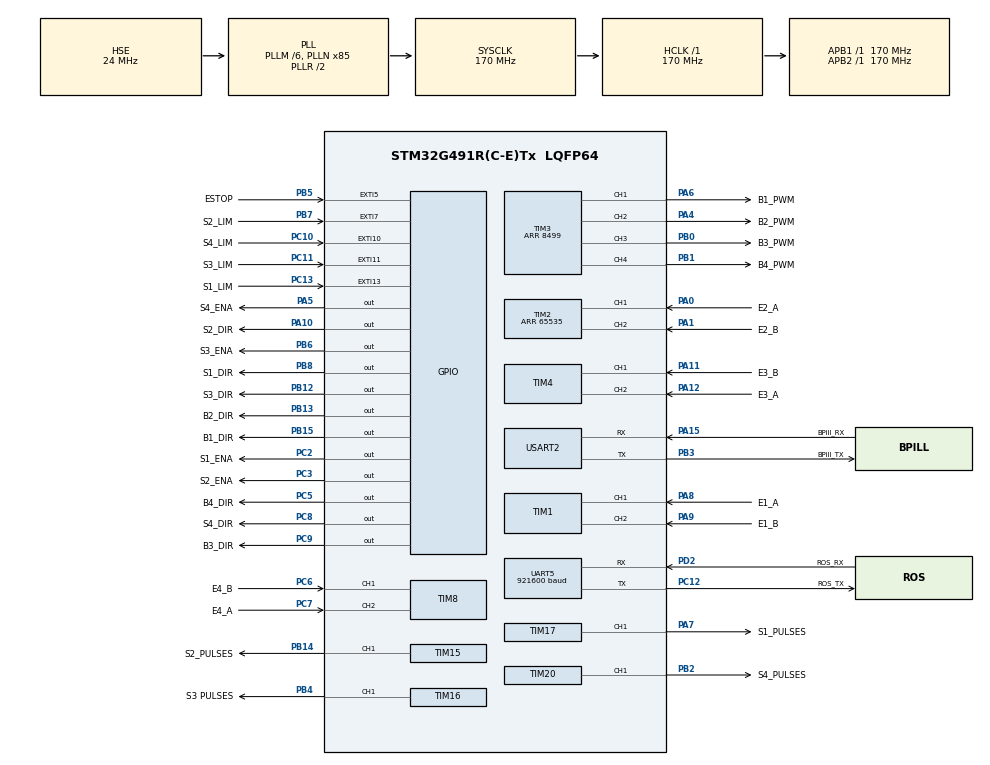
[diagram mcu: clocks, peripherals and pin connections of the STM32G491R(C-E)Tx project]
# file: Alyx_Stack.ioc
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Dma.Request0=UART5_RX
Dma.Request1=UART5_TX
Dma.UART5_RX.0.Direction=DMA_PERIPH_TO_MEMORY
Dma.UART5_RX.0.EventEnable=DISABLE
Dma.UART5_RX.0.Instance=DMA1_Channel1
Dma.UART5_RX.0.MemDataAlignment=DMA_MDATAALIGN_BYTE
Dma.UART5_RX.0.MemInc=DMA_MINC_ENABLE
Dma.UART5_RX.0.Mode=DMA_CIRCULAR
Dma.UART5_RX.0.PeriphDataAlignment=DMA_PDATAALIGN_BYTE
Dma.UART5_RX.0.PeriphInc=DMA_PINC_DISABLE
Dma.UART5_RX.0.Polarity=HAL_DMAMUX_REQ_GEN_RISING
Dma.UART5_RX.0.Priority=DMA_PRIORITY_HIGH
Dma.UART5_RX.0.RequestNumber=1
Dma.UART5_RX.0.SignalID=NONE
Dma.UART5_RX.0.SyncEnable=DISABLE
Dma.UART5_RX.0.SyncPolarity=HAL_DMAMUX_SYNC_NO_EVENT
Dma.UART5_RX.0.SyncRequestNumber=1
Dma.UART5_RX.0.SyncSignalID=NONE
Dma.UART5_TX.1.Direction=DMA_MEMORY_TO_PERIPH
Dma.UART5_TX.1.EventEnable=DISABLE
Dma.UART5_TX.1.Instance=DMA1_Channel2
Dma.UART5_TX.1.MemDataAlignment=DMA_MDATAALIGN_BYTE
Dma.UART5_TX.1.MemInc=DMA_MINC_ENABLE
Dma.UART5_TX.1.Mode=DMA_NORMAL
Dma.UART5_TX.1.PeriphDataAlignment=DMA_PDATAALIGN_BYTE
Dma.UART5_TX.1.PeriphInc=DMA_PINC_DISABLE
Dma.UART5_TX.1.Polarity=HAL_DMAMUX_REQ_GEN_RISING
Dma.UART5_TX.1.Priority=DMA_PRIORITY_MEDIUM
Dma.UART5_TX.1.RequestNumber=1
Dma.UART5_TX.1.SignalID=NONE
Dma.UART5_TX.1.SyncEnable=DISABLE
Dma.UART5_TX.1.SyncPolarity=HAL_DMAMUX_SYNC_NO_EVENT
Dma.UART5_TX.1.SyncRequestNumber=1
Dma.UART5_TX.1.SyncSignalID=NONE
Mcu.Family=STM32G4
Mcu.Name=STM32G491R(C-E)Tx
Mcu.Package=LQFP64
NVIC.DMA1_Channel1_IRQn=true\:0\:0\:false\:false\:true\:false\:true\:true
NVIC.DMA1_Channel2_IRQn=true\:0\:0\:false\:false\:true\:false\:true\:true
NVIC.EXTI15_10_IRQn=true\:0\:0\:false\:false\:true\:true\:true\:true
NVIC.EXTI9_5_IRQn=true\:0\:0\:false\:false\:true\:true\:true\:true
NVIC.PriorityGroup=NVIC_PRIORITYGROUP_4
NVIC.TIM1_BRK_TIM15_IRQn=true\:1\:0\:true\:false\:true\:true\:true\:true
NVIC.TIM1_TRG_COM_TIM17_IRQn=true\:1\:0\:true\:false\:true\:true\:true\:true
NVIC.TIM1_UP_TIM16_IRQn=true\:1\:0\:true\:false\:true\:true\:true\:true
NVIC.TIM20_UP_IRQn=true\:1\:0\:true\:false\:true\:true\:true\:true
NVIC.TIM6_DAC_IRQn=true\:5\:0\:true\:false\:true\:true\:true\:true
NVIC.UART5_IRQn=true\:3\:0\:true\:false\:true\:true\:true\:true
NVIC.USART2_IRQn=true\:3\:0\:true\:false\:true\:true\:true\:true
PA0.GPIO_Label=E2_A
PA0.Signal=S_TIM2_CH1
PA1.GPIO_Label=E2_B
PA1.Signal=S_TIM2_CH2
PA10.GPIO_Label=S2_DIR
PA10.Signal=GPIO_Output
PA11.GPIO_Label=E3_B
PA11.Signal=S_TIM4_CH1
PA12.GPIO_Label=E3_A
PA12.Signal=S_TIM4_CH2
PA13.Mode=Serial_Wire
PA13.Signal=SYS_JTMS-SWDIO
PA14.Mode=Serial_Wire
PA14.Signal=SYS_JTCK-SWCLK
PA15.GPIO_Label=BPill_RX
PA15.GPIO_PuPd=GPIO_PULLUP
PA15.Mode=Asynchronous
PA15.Signal=USART2_RX
PA4.GPIO_Label=B2_PWM
PA4.Signal=S_TIM3_CH2
PA5.GPIO_Label=S4_ENA
PA5.Signal=GPIO_Output
PA6.GPIO_Label=B1_PWM
PA6.GPIO_PuPd=GPIO_NOPULL
PA6.Signal=S_TIM3_CH1
PA7.GPIO_Label=S1_PULSES
PA7.Signal=S_TIM17_CH1
PA8.GPIO_Label=E1_A
PA8.Signal=S_TIM1_CH1
PA9.GPIO_Label=E1_B
PA9.Signal=S_TIM1_CH2
PB0.GPIO_Label=B3_PWM
PB0.Signal=S_TIM3_CH3
PB1.GPIO_Label=B4_PWM
PB1.Signal=S_TIM3_CH4
PB12.GPIO_Label=S3_DIR
PB12.Signal=GPIO_Output
PB13.GPIO_Label=B2_DIR
PB13.Signal=GPIO_Output
PB14.GPIO_Label=S2_PULSES
PB14.Signal=S_TIM15_CH1
PB15.GPIO_Label=B1_DIR
PB15.Signal=GPIO_Output
PB2.GPIO_Label=S4_PULSES
PB2.Signal=S_TIM20_CH1
PB3.GPIO_Label=BPill_TX
PB3.Mode=Asynchronous
PB3.Signal=USART2_TX
PB4.GPIO_Label=S3 PULSES
PB4.Signal=S_TIM16_CH1
PB5.GPIO_Label=ESTOP
PB5.GPIO_ModeDefaultEXTI=GPIO_MODE_IT_FALLING
PB5.GPIO_PuPd=GPIO_PULLDOWN
PB5.Signal=GPXTI5
PB6.GPIO_Label=S3_ENA
PB6.Signal=GPIO_Output
PB7.GPIO_Label=S2_LIM
PB7.GPIO_ModeDefaultEXTI=GPIO_MODE_IT_FALLING
PB7.GPIO_PuPd=GPIO_PULLDOWN
PB7.Signal=GPXTI7
PB8-BOOT0.GPIO_Label=S1_DIR
PB8-BOOT0.Signal=GPIO_Output
PC10.GPIO_Label=S4_LIM
PC10.GPIO_ModeDefaultEXTI=GPIO_MODE_IT_FALLING
PC10.GPIO_PuPd=GPIO_PULLDOWN
PC10.Signal=GPXTI10
PC11.GPIO_Label=S3_LIM
PC11.GPIO_ModeDefaultEXTI=GPIO_MODE_IT_FALLING
PC11.GPIO_PuPd=GPIO_PULLDOWN
PC11.Signal=GPXTI11
PC12.GPIO_Label=ROS_TX
PC12.Mode=Asynchronous
PC12.Signal=UART5_TX
PC13.GPIO_Label=S1_LIM
PC13.GPIO_ModeDefaultEXTI=GPIO_MODE_IT_FALLING
PC13.GPIO_PuPd=GPIO_PULLDOWN
PC13.Signal=GPXTI13
PC2.GPIO_Label=S1_ENA
PC2.Signal=GPIO_Output
PC3.GPIO_Label=S2_ENA
PC3.Signal=GPIO_Output
PC5.GPIO_Label=B4_DIR
PC5.Signal=GPIO_Output
PC6.GPIO_Label=E4_B
PC6.Signal=S_TIM8_CH1
PC7.GPIO_Label=E4_A
PC7.Signal=S_TIM8_CH2
PC8.GPIO_Label=S4_DIR
PC8.Signal=GPIO_Output
PC9.GPIO_Label=B3_DIR
PC9.Signal=GPIO_Output
PD2.GPIO_Label=ROS_RX
PD2.GPIO_PuPd=GPIO_PULLUP
PD2.Mode=Asynchronous
PD2.Signal=UART5_RX
PF0-OSC_IN.Mode=HSE-External-Oscillator
PF0-OSC_IN.Signal=RCC_OSC_IN
PF1-OSC_OUT.Mode=HSE-External-Oscillator
PF1-OSC_OUT.Signal=RCC_OSC_OUT
ProjectManager.HeapSize=0x200
ProjectManager.StackSize=0x400
ProjectManager.TargetToolchain=STM32CubeIDE
RCC.ADC12Freq_Value=170000000
RCC.ADC345Freq_Value=170000000
RCC.AHBFreq_Value=170000000
RCC.APB1Freq_Value=170000000
RCC.APB1TimFreq_Value=170000000
RCC.APB2Freq_Value=170000000
RCC.APB2TimFreq_Value=170000000
RCC.CortexFreq_Value=170000000
RCC.EXTERNAL_CLOCK_VALUE=12288000
RCC.HCLKFreq_Value=170000000
RCC.HSE_VALUE=24000000
RCC.HSI48_VALUE=48000000
RCC.HSI_VALUE=16000000
RCC.LSE_VALUE=32768
RCC.PLLM=RCC_PLLM_DIV6
RCC.PLLN=85
RCC.PLLSourceVirtual=RCC_PLLSOURCE_HSE
RCC.SYSCLKFreq_VALUE=170000000
RCC.SYSCLKSource=RCC_SYSCLKSOURCE_PLLCLK
RCC.USBFreq_Value=48000000
RCC.VCOOutputFreq_Value=340000000
SH.S_TIM15_CH1.0=TIM15_CH1,PWM Generation1 CH1
SH.S_TIM16_CH1.0=TIM16_CH1,PWM Generation1 CH1
SH.S_TIM17_CH1.0=TIM17_CH1,PWM Generation1 CH1
SH.S_TIM1_CH1.0=TIM1_CH1,Encoder_Interface
SH.S_TIM1_CH2.0=TIM1_CH2,Encoder_Interface
SH.S_TIM20_CH1.0=TIM20_CH1,PWM Generation1 CH1
SH.S_TIM2_CH1.0=TIM2_CH1,Encoder_Interface
SH.S_TIM2_CH2.0=TIM2_CH2,Encoder_Interface
SH.S_TIM3_CH1.0=TIM3_CH1,PWM Generation1 CH1
SH.S_TIM3_CH2.0=TIM3_CH2,PWM Generation2 CH2
SH.S_TIM3_CH3.0=TIM3_CH3,PWM Generation3 CH3
SH.S_TIM3_CH4.0=TIM3_CH4,PWM Generation4 CH4
SH.S_TIM4_CH1.0=TIM4_CH1,Encoder_Interface
SH.S_TIM4_CH2.0=TIM4_CH2,Encoder_Interface
SH.S_TIM8_CH1.0=TIM8_CH1,Encoder_Interface
SH.S_TIM8_CH2.0=TIM8_CH2,Encoder_Interface
TIM1.EncoderMode=TIM_ENCODERMODE_TI12
TIM1.IC1Filter=10
TIM1.IC2Filter=10
TIM15.AutoReloadPreload=TIM_AUTORELOAD_PRELOAD_ENABLE
TIM15.Channel-PWM\ Generation1\ CH1=TIM_CHANNEL_1
TIM15.OCIdleState_1=TIM_OCIDLESTATE_RESET
TIM15.OCPolarity_1=TIM_OCPOLARITY_LOW
TIM15.PeriodNoDither=3
TIM15.Prescaler=125
TIM16.AutoReloadPreload=TIM_AUTORELOAD_PRELOAD_ENABLE
TIM16.Channel=TIM_CHANNEL_1
TIM16.OCIdleState_1=TIM_OCIDLESTATE_RESET
TIM16.OCPolarity_1=TIM_OCPOLARITY_LOW
TIM16.PeriodNoDither=3
TIM16.Prescaler=125
TIM17.AutoReloadPreload=TIM_AUTORELOAD_PRELOAD_ENABLE
TIM17.Channel=TIM_CHANNEL_1
TIM17.OCIdleState_1=TIM_OCIDLESTATE_RESET
TIM17.OCPolarity_1=TIM_OCPOLARITY_LOW
TIM17.PeriodNoDither=3
TIM17.Prescaler=125
TIM2.EncoderMode=TIM_ENCODERMODE_TI12
TIM2.IC1Filter=10
TIM2.IC2Filter=10
TIM2.PeriodNoDither=65535
TIM20.AutoReloadPreload=TIM_AUTORELOAD_PRELOAD_ENABLE
TIM20.Channel-PWM\ Generation1\ CH1=TIM_CHANNEL_1
TIM20.OCIdleState_1=TIM_OCIDLESTATE_RESET
TIM20.OCPolarity_1=TIM_OCPOLARITY_LOW
TIM20.PeriodNoDither=3
TIM20.Prescaler=125
TIM3.Channel-PWM\ Generation1\ CH1=TIM_CHANNEL_1
TIM3.Channel-PWM\ Generation2\ CH2=TIM_CHANNEL_2
TIM3.Channel-PWM\ Generation3\ CH3=TIM_CHANNEL_3
TIM3.Channel-PWM\ Generation4\ CH4=TIM_CHANNEL_4
TIM3.PeriodNoDither=8499
TIM4.EncoderMode=TIM_ENCODERMODE_TI12
TIM4.IC1Filter=10
TIM4.IC2Filter=10
TIM6.PeriodNoDither=9999
TIM6.Prescaler=169
TIM8.EncoderMode=TIM_ENCODERMODE_TI12
TIM8.IC1Filter=10
TIM8.IC2Filter=10
UART5.BaudRate=921600
USART2.VirtualMode-Asynchronous=VM_ASYNC
VP_SYS_VS_DBSignals.Mode=DisableDeadBatterySignals
VP_TIM15_VS_OPM.Mode=OPM_bit
VP_TIM16_VS_ClockSourceINT.Mode=Enable_Timer
VP_TIM16_VS_OPM.Mode=OPM_bit
VP_TIM17_VS_ClockSourceINT.Mode=Enable_Timer
VP_TIM17_VS_OPM.Mode=OPM_bit
VP_TIM20_VS_OPM.Mode=OPM_bit
VP_TIM6_VS_ClockSourceINT.Mode=Enable_Timer
board=custom

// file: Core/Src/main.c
/* USER CODE BEGIN Header */
/**
  ******************************************************************************
  * @file           : main.c
  * @brief          : Main program body
  ******************************************************************************
  * @attention
  *
  * Copyright (c) 2025 STMicroelectronics.
  * All rights reserved.
  *
  * This software is licensed under terms that can be found in the LICENSE file
  * in the root directory of this software component.
  * If no LICENSE file comes with this software, it is provided AS-IS.
  *
  ******************************************************************************
  */
/* USER CODE END Header */
#include "main.h"

/* USER CODE BEGIN Includes */
#include "motor_driver.h"
#include "encoder.h"
#include "pid_controller.h"
#include "Stepperv2.h"
#include "globals.h"
#include "telemetry.h"
#include <string.h>
#include <stdio.h>
#include <ctype.h>   // isspace
#include <stdlib.h>  // strtol & strtof
#include <math.h>

/* ---- TELEMETRY v2 BUILD (fake-ALYX validation session) --------------------
 * Full vehicle: homing, limit switches and the safety board work normally.
 *
 * TELEMETRY_OWNS_UART5 1: UART5 runs at 921600 and carries telemetry v2 rows
 *   (Core/Src/telemetry.c). The "@" ROS feedback and the 3-byte mode echo on
 *   UART5 are off, so nothing else writes to that port. Commands still come in
 *   on UART5 in the usual "S1 <deg>; B1 <rpm>;" format, plus "#SCN <n>;" tags.
 *   NOTE: the baud rate is set in MX_UART5_Init and Alyx_Stack.ioc (921600);
 *   set both back to 115200 for the normal ROS build.
 * TEST_BENCH_MODE 1: escape hatch only, if the Black Pill link dies mid-session.
 *   It ignores the Black Pill heartbeat, i.e. the WIRELESS E-STOP IS OFF.
 *   Wired e-stop still works. Leave at 0.
 */
#define TELEMETRY_OWNS_UART5 1
#define TEST_BENCH_MODE 1	// set 1 if no bpill for heartbeat
/* USER CODE END Includes */

/* USER CODE BEGIN PD */
#define CTRL_Loop_Period (1.0f / CTRL_Loop_Freq)
#define ENCODERS_CPR 1993			// bilda motors
//#define ENCODERS_CPR 92733		// old rhino motors
#define DEBOUNCE_TIME_PERIOD 50		// debounce time for lim switches
#define Stepper_Microsteps 1
#define Stepper_Motor_Steps_Per_Rev 800
//#define Stepper_Motor_Steps_Per_Rev 1600
#define Stepper_Steps_Per_Rev (Stepper_Motor_Steps_Per_Rev * Stepper_Microsteps)
#define rx_buf_size 64
#define feedback_buf_size 512
#define feedback_transmission_freq 200
#define BPillHeartbeatTime 300
/* USER CODE END PD */

/* USER CODE BEGIN PM */
PID_Handle_t pid_b1;
PID_Handle_t pid_b2;
PID_Handle_t pid_b3;
PID_Handle_t pid_b4;
// numbering system
// 1   2
// 3   4
// for back-left motors
Motor_Handle_t B1; 		// B -> BDC
Motor_Handle_t B2;
Motor_Handle_t B3;
Motor_Handle_t B4;
Encoder_Handle_t E1; 	// E -> Encoder
Encoder_Handle_t E2;
Encoder_Handle_t E3;
Encoder_Handle_t E4;
Stepper_Handle_t S1;	// S -> Stepper
Stepper_Handle_t S2;
Stepper_Handle_t S3;
Stepper_Handle_t S4;
/* USER CODE END PM */

TIM_HandleTypeDef htim1;
TIM_HandleTypeDef htim2;
TIM_HandleTypeDef htim3;
TIM_HandleTypeDef htim4;
TIM_HandleTypeDef htim6;
TIM_HandleTypeDef htim8;
TIM_HandleTypeDef htim15;
TIM_HandleTypeDef htim16;
TIM_HandleTypeDef htim17;
TIM_HandleTypeDef htim20;

UART_HandleTypeDef huart5;
UART_HandleTypeDef huart2;
DMA_HandleTypeDef hdma_uart5_rx;
DMA_HandleTypeDef hdma_uart5_tx;

/* USER CODE BEGIN PV */
// Encoder + RPM vars
//BDC motors
volatile int b1_target_rpm = 0;
volatile int b2_target_rpm = 0;
volatile int b3_target_rpm = 0;
volatile int b4_target_rpm = 0;
volatile float b1_current_rpm = 0.0f;
volatile float b2_current_rpm = 0.0f;
volatile float b3_current_rpm = 0.0f;
volatile float b4_current_rpm = 0.0f;
float b1_control_signal = 0.0f;		// PID output - more responsive than taman with headphones on
float b2_control_signal = 0.0f;
float b3_control_signal = 0.0f;
float b4_control_signal = 0.0f;

// stepper motor
volatile int s1_target_angle = 0;
volatile int s2_target_angle = 0;
volatile int s3_target_angle = 0;
volatile int s4_target_angle = 0;

// homing steppers
volatile uint32_t last_debounce_time[4] = {0, 0, 0, 0};
volatile uint32_t current_debounce_time = 0;

volatile uint8_t control_loop = 0;		// control loop flag

// USB - USki Baat sunle lolololololol
//uint8_t instruct_buffer[64];
//volatile uint8_t usb_data_ready = 0;	// im ready for a date-a...get it? coz like...

uint8_t rx_buf[rx_buf_size];
uint8_t rx_byte;
volatile int rx_idx = 0;
volatile uint8_t callback_flag = 0;
uint8_t feedback_buf[feedback_buf_size];
volatile uint8_t uart_data_ready = 0;
uint8_t shadow_rx_buf[rx_buf_size * 2]; // This is the CPU's private copy: large to hold accumulations
char main_cmd_buf[256];                 // The CPU parses this in the while(1) loop
char cmd_work_buf[256];                 // main loop's private copy (telemetry build)
uint32_t lastTransmissionTime = 0;

// UART stop waala error (YOU ARE T) lololol
volatile uint8_t error_entered = 0;
volatile uint32_t last_error;
volatile uint8_t uarterror = 0;
volatile uint32_t uarterror3_error;

//uint32_t last_cmd_time = 0;
//volatile uint8_t wdt_active = 0; // indicate teleop watchdog has taken control
volatile uint8_t estop_active = 0;
volatile uint8_t estop_action_done = 0;

volatile uint32_t last_bpill_hearbeat = 0;		// for software watchdog
uint32_t last_mode_tx = 0;                   // periodic transmission
volatile uint8_t wireless_estop_active = 0;  // bpill flags
uint8_t initial_homing_done = 0;
volatile uint8_t homing_active = 1;		// boot-up homing is protected with 1
uint32_t idle_teleop_force = 0;

volatile uint8_t bpill_rx_buf[3];
uint8_t bpill_rx_byte;          // Buffer for 1 byte
volatile uint8_t bpill_rx_state = 0;
uint8_t bpill_sync_state = 0;   // Keeps track of where we are in the packet
uint8_t bpill_tx_buf[3];

static float current_kp = 0.004893002197721693f;		// par kp toh senior he lmaoooo
static float current_ki = 0.02823752341330259f;
static float current_kd = 0.00013409059780944936f;

volatile uint8_t uart_tx_ready = 1;
int flag = 0;
/* USER CODE END PV */

void SystemClock_Config(void);
static void MX_GPIO_Init(void);
static void MX_DMA_Init(void);
static void MX_TIM1_Init(void);
static void MX_TIM2_Init(void);
static void MX_TIM4_Init(void);
static void MX_TIM8_Init(void);
static void MX_TIM3_Init(void);
static void MX_TIM6_Init(void);
static void MX_TIM15_Init(void);
static void MX_TIM17_Init(void);
static void MX_TIM20_Init(void);
static void MX_UART5_Init(void);
static void MX_TIM16_Init(void);
static void MX_USART2_UART_Init(void);

/* USER CODE BEGIN 0 */
void TIM6_SetPeriod_us(uint32_t period_us)
{
    uint32_t timer_clk = HAL_RCC_GetPCLK1Freq();
    if ((RCC->CFGR & RCC_CFGR_PPRE1) != RCC_CFGR_PPRE1_DIV1)
        timer_clk *= 2;

    // Choose prescaler so timer ticks at 1 MHz (1 tick = 1 µs)
    uint32_t presc = (timer_clk / 1000000UL) - 1;

    TIM6->PSC = presc;
    TIM6->ARR = period_us - 1;

    TIM6->EGR = TIM_EGR_UG;   // load PSC & ARR immediately
}
void DWT_Init(void)
{
    CoreDebug->DEMCR |= CoreDebug_DEMCR_TRCENA_Msk;

    DWT->CTRL &= ~DWT_CTRL_CYCCNTENA_Msk;
    DWT->CYCCNT = 0;
    DWT->CTRL |= DWT_CTRL_CYCCNTENA_Msk;
}

void delay_us(uint32_t us) {
    uint32_t start = DWT->CYCCNT;
    uint32_t cycles = us * (SystemCoreClock / 1000000);
    while ((DWT->CYCCNT - start) < cycles);
}

static inline float clamp_deg_180_pos(float a)
{
    a = fmodf(a, 360.0f);

    if (a <= -180.0f) a += 360.0f;  // -180 → +180
    if (a >  180.0f)  a -= 360.0f;

    return a;   // (-180, 180]
}

typedef enum {
	MODE_ESTOP = 0x00,
	MODE_HOMING = 0x01,
	MODE_TELEOP = 0x02,
	MODE_AUTONAV = 0x03,
	MODE_SELFDRIVE = 0x04,
	MODE_IDLE = 0x05
} MODES;

float angles[4] = {180.00f*5, 90.00f*5, 30.00f*5, 90.00f*5};
uint8_t i = 0;
//MODES mode = MODE_HOMING;
//MODES prev_rec_mode = MODE_IDLE, rec_mode = MODE_IDLE;
MODES prev_rec_mode = MODE_TELEOP, rec_mode = MODE_TELEOP;
uint8_t sending_mode = 0;
volatile MODES ros2_mode = MODE_HOMING;
MODES current_true_mode = MODE_HOMING;	// so that nucleo sends wired estop to bpill
MODES last_sent_mode = (MODES)0xFF;		// warning: could be fucky?

//float map_rpm_to_signal(float rpm) {
//
//    if (rpm > 100.0f) return 0.8f;
//    if (rpm < 0.0f)   return 0.0f;
//
//    // multiplication factor (0.8 / 100 = 0.008)
//    return rpm * 0.008f;
//}

float c_angle = 0.0f;
int c_rpm = 120;
int cmd_count = 0;

int prev_rpm = 100;
/* USER CODE END 0 */

int main(void)
{

  /* MCU Configuration--------------------------------------------------------*/

  /* Reset of all peripherals, Initializes the Flash interface and the Systick. */
  HAL_Init();

  /* Configure the system clock */
  SystemClock_Config();

  /* Initialize all configured peripherals */
  MX_GPIO_Init();
  MX_DMA_Init();
  MX_TIM1_Init();
  MX_TIM2_Init();
  MX_TIM4_Init();
  MX_TIM8_Init();
  MX_TIM3_Init();
  MX_TIM6_Init();
  MX_TIM15_Init();
  MX_TIM17_Init();
  MX_TIM20_Init();
  MX_UART5_Init();
  MX_TIM16_Init();
  MX_USART2_UART_Init();
  /* USER CODE BEGIN 2 */
  // PID Instances
  PID_Create(&pid_b1, current_kp, current_ki, current_kd, CTRL_Loop_Period);
  PID_Create(&pid_b2, current_kp, current_ki, current_kd, CTRL_Loop_Period);
  PID_Create(&pid_b3, current_kp, current_ki, current_kd, CTRL_Loop_Period);
  PID_Create(&pid_b4, current_kp, current_ki, current_kd, CTRL_Loop_Period);

  // Motors
  Motor_Create(&B1, &htim3, TIM_CHANNEL_1, GPIOB, GPIO_PIN_15);
  Motor_Create(&B2, &htim3, TIM_CHANNEL_2, GPIOB, GPIO_PIN_13);
  Motor_Create(&B3, &htim3, TIM_CHANNEL_3, GPIOC, GPIO_PIN_9);
  Motor_Create(&B4, &htim3, TIM_CHANNEL_4, GPIOC, GPIO_PIN_5);

  // Motor encoders
  Encoder_Create(&E1, &htim1, ENCODERS_CPR);
  Encoder_Create(&E2, &htim2, ENCODERS_CPR);
  Encoder_Create(&E3, &htim4, ENCODERS_CPR);
  Encoder_Create(&E4, &htim8, ENCODERS_CPR);

  // Steppers
  Stepper_Create(&S1, &htim17, TIM_CHANNEL_1, GPIOB, GPIO_PIN_8, 0, 0, Stepper_Motor_Steps_Per_Rev * 5, 0, 1, 1, -96, -127, -94);	// -99
  Stepper_Create(&S2, &htim15, TIM_CHANNEL_1, GPIOA, GPIO_PIN_10, 0, 0, Stepper_Motor_Steps_Per_Rev * 5, 0, 1, 1, -96, -120, -86);	// -92
  Stepper_Create(&S3, &htim16, TIM_CHANNEL_1, GPIOB, GPIO_PIN_12, 0, 0, Stepper_Motor_Steps_Per_Rev * 5, 0, 1, 1, -97, -125, -90);	// -95
  Stepper_Create(&S4, &htim20, TIM_CHANNEL_1, GPIOC, GPIO_PIN_8, 0, 0, Stepper_Motor_Steps_Per_Rev * 5, 0, 1, 1, -97, -123, -90);	// -94

  initTimer(&S1);
  initTimer(&S2);
  initTimer(&S3);
  initTimer(&S4);

  // timer period callback

  uint32_t period_us = 1000000 / CTRL_Loop_Freq;
  //TIM6_SetPeriod_us((1.0f/CTRL_Loop_Freq) * 1000000);
  TIM6_SetPeriod_us(period_us);
  DWT_Init();

  //Stepper_Create(&stepper_handle_BL, &htim17, TIM_CHANNEL_1, STEP_BL_DIR_GPIO_Port,  STEP_BL_DIR_Pin, STEP_BL_ENA_GPIO_Port, STEP_BL_ENA_Pin, Stepper_Steps_Per_Rev);

  PID_SetOutputLimits(&pid_b1, -0.8f, 0.8f);
  PID_SetDeadbands(&pid_b1, 0.5f, 1.0f);
  PID_SetIntegralDecay(&pid_b1, 0.9f);
  PID_SetMaxSlewRate(&pid_b1, 10.0f);		// tune later

  PID_SetOutputLimits(&pid_b2, -0.8f, 0.8f);
  PID_SetDeadbands(&pid_b2, 0.5f, 1.0f);
  PID_SetIntegralDecay(&pid_b2, 0.9f);
  PID_SetMaxSlewRate(&pid_b2, 10.0f);		// tune later

  PID_SetOutputLimits(&pid_b3, -0.8f, 0.8f);
  PID_SetDeadbands(&pid_b3, 0.5f, 1.0f);
  PID_SetIntegralDecay(&pid_b3, 0.9f);
  PID_SetMaxSlewRate(&pid_b3, 10.0f);		// tune later

  PID_SetOutputLimits(&pid_b4, -0.8f, 0.8f);
  PID_SetDeadbands(&pid_b4, 0.5f, 1.0f);
  PID_SetIntegralDecay(&pid_b4, 0.9f);
  PID_SetMaxSlewRate(&pid_b4, 10.0f);		// tune later

  // back left arm setup
  Encoder_Start(&E1);
  Encoder_Start(&E2);
  Encoder_Start(&E3);
  Encoder_Start(&E4);  // Tim4 - Encoder
  //HAL_TIM_PWM_Start(&htim1, TIM_CHANNEL_3); // B1
  //HAL_TIM_PWM_Start(&htim2, TIM_CHANNEL_3); // B2
  HAL_TIM_PWM_Start(&htim3, TIM_CHANNEL_1);
  HAL_TIM_PWM_Start(&htim3, TIM_CHANNEL_2); // B3
  HAL_TIM_PWM_Start(&htim3, TIM_CHANNEL_3);
  HAL_TIM_PWM_Start(&htim3, TIM_CHANNEL_4);
  //HAL_TIM_PWM_Start(&htim8, TIM_CHANNEL_3); // B4
  HAL_TIM_Base_Start_IT(&htim6);	//scheduling interrupts

  HAL_UARTEx_ReceiveToIdle_DMA(&huart5, rx_buf, rx_buf_size);	// for incoming ros commands
  HAL_UART_Receive_IT(&huart2, &bpill_rx_byte, 1);					// listen to black pill for mode instructions

  tel_init();

#if TEST_BENCH_MODE
  rec_mode = MODE_TELEOP;
#endif
  /* USER CODE END 2 */

  /* Infinite loop */
  /* USER CODE BEGIN WHILE */
  S1.homing_status = 0;
  S2.homing_status = 0;
  S3.homing_status = 0;
  S4.homing_status = 0;
  while (1)
  {

	  // timeout after initial homing
	  uint8_t heartbeat_timeout = (HAL_GetTick() - last_bpill_hearbeat > BPillHeartbeatTime);
	  if (homing_active && ros2_mode == MODE_HOMING){
		  heartbeat_timeout = 0;
	  }
#if TEST_BENCH_MODE
	  heartbeat_timeout = 0;              /* escape hatch only */
	  last_bpill_hearbeat = HAL_GetTick();
#endif
	  wireless_estop_active = (heartbeat_timeout) || (rec_mode == MODE_ESTOP);

	  // NUCLEO owns mode
//	  if (estop_active || wireless_estop_active) {
	  if (estop_active) {
	      current_true_mode = MODE_ESTOP;
	  }
	  else {								// neither Estop active - rotary switch takes control
	      current_true_mode = ros2_mode;
	  }

//	  // software watchdog for bpill instructions (can't use rn because of keyboard tele-op node)
//	  if ((HAL_GetTick() - last_bpill_hearbeat) > 500){
//		  mode = MODE_ESTOP;
//		  estop_active = 1;
//	  }

	  //if (current_true_mode == MODE_IDLE) current_true_mode = MODE_TELEOP; //forcing teleop instead of idle for now, will change when switches.

	  // telemetry
	  if ((last_sent_mode != current_true_mode) || (HAL_GetTick() - last_mode_tx > 100)){				// telemetry and safety comms
		  bpill_tx_buf[0] = 0xAA;
		  bpill_tx_buf[1] = current_true_mode;
		  bpill_tx_buf[2] = bpill_tx_buf[0] ^ bpill_tx_buf[1];
		  HAL_UART_Transmit(&huart2, bpill_tx_buf, 3, 10);
#if !TELEMETRY_OWNS_UART5
		  HAL_UART_Transmit(&huart5, bpill_tx_buf, 3, 10);
#endif
		  last_sent_mode = current_true_mode;
		  last_mode_tx = HAL_GetTick();
	  }

	  if (uart_data_ready){
#if TELEMETRY_OWNS_UART5
		  // at 921600 a new chunk can arrive before this block runs: the RX
		  // callback appends to main_cmd_buf while uart_data_ready is set, and
		  // we take the whole block atomically here
		  __disable_irq();
		  strcpy(cmd_work_buf, main_cmd_buf);
		  main_cmd_buf[0] = '\0';
		  uart_data_ready = 0;
		  __enable_irq();
		  char *scn = strstr(cmd_work_buf, "#SCN");
		  if (scn) {
			  const char *sp = (const char *)(scn + 4);
			  tel_set_scenario((uint8_t)parse_cmd(&sp));
		  }
		  // frame tags "#F <n>;": note the last one (several may be in one block)
		  {
			  char *fr = NULL, *q = cmd_work_buf;
			  while ((q = strstr(q, "#F")) != NULL) { fr = q; q += 2; }
			  if (fr) {
				  const char *fp = (const char *)(fr + 2);
				  tel_note_frame((uint16_t)parse_cmd(&fp));
			  }
		  }
		  char *cmd_buf = cmd_work_buf;
#else
		  uart_data_ready = 0;
		  char *cmd_buf = main_cmd_buf;
#endif
		  int new_mode = parse_mode(cmd_buf);

		  if (new_mode >= 0 && new_mode <= 5){

			  // Ignore ESTOP and homing commands from ROS2
			  if (new_mode != MODE_ESTOP && new_mode != MODE_HOMING) {
				  if (!homing_active){
					  ros2_mode = (MODES)new_mode;
				  }
			  }

			  if (estop_active || wireless_estop_active){
			  //if (estop_active) {
				  current_true_mode = MODE_ESTOP;
			  }
			  else {
				  current_true_mode = ros2_mode;
			  }
		  }
		  // motor parser runs only in safe driving mode
		  if (current_true_mode == MODE_TELEOP ||
			  current_true_mode == MODE_AUTONAV ||
			  current_true_mode == MODE_SELFDRIVE){
			  handle_command(cmd_buf);
		  }
		  cmd_buf[0] = '\0';
	  }

	  switch(current_true_mode){

	  case MODE_ESTOP:
		  b1_target_rpm = b2_target_rpm = b3_target_rpm = b4_target_rpm = 0;
//		  Motor_SetOutput(&B1, 0.0f);
//		  Motor_SetOutput(&B2, 0.0f);
//		  Motor_SetOutput(&B3, 0.0f);
//		  Motor_SetOutput(&B4, 0.0f);
//
//		  PID_Reset(&pid_b1);
//		  PID_Reset(&pid_b2);
//		  PID_Reset(&pid_b3);
//		  PID_Reset(&pid_b4);

		// preempt normal movements so they cleanly stop and calculate exact absolute angles
		// we only do this if we haven't already started the return-to-zero sequence
		if (!estop_action_done) {
			if (S1.isMoving) S1.pending_preemption = 1;
			if (S2.isMoving) S2.pending_preemption = 1;
			if (S3.isMoving) S3.pending_preemption = 1;
			if (S4.isMoving) S4.pending_preemption = 1;

			// yaw-estop-yaw fails the motordriver.c check for lastInstruct because last is still yaw angle so gets skipped
			S1.lastInstruct.degree = 0;
			S2.lastInstruct.degree = 0;
			S3.lastInstruct.degree = 0;
			S4.lastInstruct.degree = 0;
		}

		// once steppers naturally halt and update their angles, trigger zeroing
		if (!S1.isMoving && !S2.isMoving && !S3.isMoving && !S4.isMoving) {
		  if (!estop_action_done) {
			  estop_action_done = 1;

			  if (S1.homing_status) moveAngleAbsolute(&S1, 0, 30, &B1);
			  if (S2.homing_status) moveAngleAbsolute(&S2, 0, 30, &B2);
			  if (S3.homing_status) moveAngleAbsolute(&S3, 0, 30, &B3);
			  if (S4.homing_status) moveAngleAbsolute(&S4, 0, 30, &B4);

			  initWQueue(&S1.q); initWQueue(&S2.q); initWQueue(&S3.q); initWQueue(&S4.q);
		  }
		}

		  if (HAL_GPIO_ReadPin(ESTOP_GPIO_Port, ESTOP_Pin) == GPIO_PIN_SET && !wireless_estop_active) {
			  estop_active = 0;
			  estop_action_done = 0;		// for releasing locked steppers at zero on e-stop

			  // default to idle
			  // ros2_mode = MODE_IDLE;
			  ros2_mode = MODE_TELEOP;
			  b1_target_rpm = b2_target_rpm = b3_target_rpm = b4_target_rpm = 0;

			  // purge stepper queues for ros2 spam
			  initWQueue(&S1.q); initWQueue(&S2.q);
			  initWQueue(&S3.q); initWQueue(&S4.q);
			  main_cmd_buf[0] = '\0';
		}

		  break;

	  case MODE_HOMING:

		  if(S1.correctOffset == 1){
			  moveAngle(&S1, -S1.limSwitchOffset, 30);
			  S1.correctOffset = 2;
		  }
		  if(S2.correctOffset == 1){
			  moveAngle(&S2, -S2.limSwitchOffset, 30);
			  S2.correctOffset = 2;
		  }
		  if(S3.correctOffset == 1){
			  moveAngle(&S3, -S3.limSwitchOffset, 30);
			  S3.correctOffset = 2;
		  }
		  if(S4.correctOffset == 1){
			  moveAngle(&S4, -S4.limSwitchOffset, 30);
			  S4.correctOffset = 2;
		  }

		  if(!S1.homing_status && !S1.isMoving && !S1.totalPulses){
			  moveAngle(&S1, -360, 10);
			  tel_homing_sweep_start(0);
		  }
		  if(!S2.homing_status && !S2.isMoving && !S2.totalPulses){
			  moveAngle(&S2, -360, 10);
			  tel_homing_sweep_start(1);
		  }
		  if(!S3.homing_status && !S3.isMoving && !S3.totalPulses){
			  moveAngle(&S3, -360, 10);
			  tel_homing_sweep_start(2);
		  }
		  if(!S4.homing_status && !S4.isMoving && !S4.totalPulses){
			  moveAngle(&S4, -360, 10);
			  tel_homing_sweep_start(3);
		  }
		  if(S1.homing_status && S2.homing_status && S3.homing_status && S4.homing_status){
			  //ros2_mode = MODE_IDLE;	// go idle post homing
			  ros2_mode = MODE_TELEOP;	// go teleop post homing
//			  if (!initial_homing_done){
//				  initial_homing_done = 1;
//				  last_bpill_hearbeat = HAL_GetTick();
//			  }
			  if (homing_active){
				  homing_active = 0;
				  last_bpill_hearbeat = HAL_GetTick();
			  }
		  }
		  break;

	  case MODE_IDLE:
		  //b1_target_rpm = b2_target_rpm = b3_target_rpm = b4_target_rpm = 0;
		  //current_true_mode = MODE_TELEOP;
		  //break;
		  // IDLE WAS ACTUALLLY A THING - TEAM CAPTAIN ONAS CHATURVEDI MADE US REMOVE IT. HUM CHUTIYE NAHI HE WE SWEAR

	  case MODE_AUTONAV:

	  case MODE_SELFDRIVE:

	  case MODE_TELEOP:

//		  if (estop_active){
//			  if (HAL_GPIO_ReadPin(ESTOP_GPIO_Port, ESTOP_Pin) == GPIO_PIN_SET){
//				  estop_active = 0;
//				  estop_action_done = 0;		// for releasing locked steppers at zero on e-stop
//			  }
//		  }

//		  if (uart_data_ready) {
//			uart_data_ready = 0;
//			if (!estop_active){
//				//last_cmd_time = HAL_GetTick();
//				handle_command(main_cmd_buf);
//			}
//		  }

		  // so that new parsing doesnt parse P.A.I.N (bas failsafe in case estop press ke baad bhi instructions aa rahe he)
		  // oh also - FUCK EMI

//		  // E-stop provisions
//		  if (estop_active) {
//			  b1_target_rpm = b2_target_rpm = b3_target_rpm = b4_target_rpm = 0;
//			  	// preempt normal movements so they cleanly stop and calculate exact absolute angles
//				// we only do this if we haven't already started the return-to-zero sequence
//				if (!estop_action_done) {
//					if (S1.isMoving) S1.pending_preemption = 1;
//					if (S2.isMoving) S2.pending_preemption = 1;
//					if (S3.isMoving) S3.pending_preemption = 1;
//					if (S4.isMoving) S4.pending_preemption = 1;
//
//					// yaw-estop-yaw fails the motordriver.c check for lastInstruct because last is still yaw angle so gets skipped
//					S1.lastInstruct.degree = 0;
//					S2.lastInstruct.degree = 0;
//					S3.lastInstruct.degree = 0;
//					S4.lastInstruct.degree = 0;
//				}
//
//				// once steppers naturally halt and update their angles, trigger zeroing
//				if (!S1.isMoving && !S2.isMoving && !S3.isMoving && !S4.isMoving) {
//				  if (!estop_action_done) {
//					  estop_action_done = 1;
//
//					  if (S1.homing_status) moveAngleAbsolute(&S1, 0, 30, &B1);
//					  if (S2.homing_status) moveAngleAbsolute(&S2, 0, 30, &B2);
//					  if (S3.homing_status) moveAngleAbsolute(&S3, 0, 30, &B3);
//					  if (S4.homing_status) moveAngleAbsolute(&S4, 0, 30, &B4);
//
//					  initWQueue(&S1.q); initWQueue(&S2.q); initWQueue(&S3.q); initWQueue(&S4.q);
//				  }
//				}
//
//		  }

		  // ! software watchdog to make sure continuous commands are received !

//		  if (HAL_GetTick() - last_cmd_time > Command_WDT_Max_Time){
//			  // software watchdog for teleop commands
//			  if (!wdt_active){
//
//				  wdt_active = 1;
//
//				  b1_target_rpm = b2_target_rpm = b3_target_rpm = b4_target_rpm = 0;
//				  if (S1.homing_status) moveAngleAbsolute(&S1, 0, 30, &B1);
//				  if (S2.homing_status) moveAngleAbsolute(&S2, 0, 30, &B2);
//				  if (S3.homing_status) moveAngleAbsolute(&S3, 0, 30, &B3);
//				  if (S4.homing_status) moveAngleAbsolute(&S4, 0, 30, &B4);
//				  initWQueue(&S1.q); initWQueue(&S2.q); initWQueue(&S3.q); initWQueue(&S4.q);
//			  }
//		  }

		  //if (!estop_active && !wdt_active){
		  if (!estop_active){
			  if(!S1.isMoving && !WisEmpty(&S1.q) && !S1.pending_preemption){
				  Wrapper temp = dequeueW(&S1.q);
				  moveAngleAbsolute(&S1, temp.degree, temp.rpm, &B1);
			  }
			  if(!S2.isMoving && !WisEmpty(&S2.q) && !S2.pending_preemption){
				  Wrapper temp = dequeueW(&S2.q);
				  moveAngleAbsolute(&S2, temp.degree, temp.rpm, &B2);
			  }
			  if(!S3.isMoving && !WisEmpty(&S3.q) && !S3.pending_preemption){
				  Wrapper temp = dequeueW(&S3.q);
				  moveAngleAbsolute(&S3, temp.degree, temp.rpm, &B3);
			  }
			  if(!S4.isMoving && !WisEmpty(&S4.q) && !S4.pending_preemption){
				  Wrapper temp = dequeueW(&S4.q);
				  moveAngleAbsolute(&S4, temp.degree, temp.rpm, &B4);
			  }
		  }

		  break;

	  default:
		  break;
	  }

		if (control_loop){
			b1_current_rpm = Encoder_GetSpeedRPM(&E1);
			b2_current_rpm = Encoder_GetSpeedRPM(&E2);
			b3_current_rpm = Encoder_GetSpeedRPM(&E3);
			b4_current_rpm = Encoder_GetSpeedRPM(&E4);

			if (current_true_mode == MODE_ESTOP){
				  Motor_SetOutput(&B1, 0.0f);
				  Motor_SetOutput(&B2, 0.0f);
				  Motor_SetOutput(&B3, 0.0f);
				  Motor_SetOutput(&B4, 0.0f);

				  PID_Reset(&pid_b1);
				  PID_Reset(&pid_b2);
				  PID_Reset(&pid_b3);
				  PID_Reset(&pid_b4);
			}
			else {
				b1_control_signal = PID_Compute(&pid_b1, (float)B1.mode ? -b1_target_rpm : b1_target_rpm, b1_current_rpm);
				//b1_control_signal = map_rpm_to_signal((float)b1_target_rpm);
				Motor_SetOutput(&B1, b1_control_signal);

				b2_control_signal = PID_Compute(&pid_b2, (float)B2.mode ? b2_target_rpm : -b2_target_rpm, b2_current_rpm);
				Motor_SetOutput(&B2, b2_control_signal);

				b3_control_signal = PID_Compute(&pid_b3, (float)B3.mode ? -b3_target_rpm : b3_target_rpm, b3_current_rpm);
				Motor_SetOutput(&B3, b3_control_signal);

				b4_control_signal = PID_Compute(&pid_b4, (float)B4.mode ? -b4_target_rpm : b4_target_rpm, b4_current_rpm);
				Motor_SetOutput(&B4, b4_control_signal);
			}

#if TELEMETRY_OWNS_UART5
			{
				tel_wheel_t tw[4];
				Encoder_Handle_t *te[4] = {&E1, &E2, &E3, &E4};
				Stepper_Handle_t *ts[4] = {&S1, &S2, &S3, &S4};
				Motor_Handle_t *tb[4] = {&B1, &B2, &B3, &B4};
				float trpm[4] = {b1_current_rpm, b2_current_rpm, b3_current_rpm, b4_current_rpm};
				int ttgt[4] = {b1_target_rpm, b2_target_rpm, b3_target_rpm, b4_target_rpm};
				float tout[4] = {b1_control_signal, b2_control_signal, b3_control_signal, b4_control_signal};
				for (int k = 0; k < 4; k++) {
					tw[k].enc_raw = (uint16_t)te[k]->last_count;
					tw[k].rpm_filt = trpm[k];
					tw[k].target_rpm = (int16_t)ttgt[k];
					tw[k].out = (current_true_mode == MODE_ESTOP) ? 0.0f : tout[k];
					tw[k].abs_step = (int32_t)ts[k]->abs_step_count;
					tw[k].cmd_deg = (int16_t)ts[k]->lastInstruct.degree;
					tw[k].flags = (tb[k]->mode ? TEL_FL_MODE : 0)
					            | (ts[k]->isMoving ? TEL_FL_MOVING : 0)
					            | (ts[k]->pending_preemption ? TEL_FL_PREEMPT : 0)
					            | (ts[k]->homing_status ? TEL_FL_HOMED : 0)
					            | (ts[k]->correctOffset ? TEL_FL_OFFSET : 0);
				}
				tel_push4(tw, (uint8_t)current_true_mode,
				          (uint8_t)((estop_active ? 1 : 0) | (wireless_estop_active ? 2 : 0)));
			}
#else
			if (HAL_GetTick() - lastTransmissionTime >= 1000/feedback_transmission_freq){
//					 if (last_sent_mode != mode){
//
//						  bpill_tx_buf[0] = 0xAA;
//						  bpill_tx_buf[1] = (uint8_t)mode;
//						  bpill_tx_buf[2] = bpill_tx_buf[0] ^ bpill_tx_buf[1];
//						  //HAL_UART_Transmit(&huart5, bpill_tx_buf, 3, 10);
//						  HAL_UART_Transmit(&huart2, bpill_tx_buf, 3, 10);
//						  //sending_mode++;		// remove after testing
//						  last_sent_mode = mode;
//					 }

				 if (uart_tx_ready)
				 {
					int tel_len = snprintf((char*)feedback_buf, feedback_buf_size,
											"@S1%ld;S2%ld;S3%ld;S4%ld;"
											//"B1%.4f;B2%.4f;B3%.4f;B4%.4f;"
											"B1%d;B2%d;B3%d;B4%d;\r\n",
											S1.abs_step_count, S2.abs_step_count,
											S3.abs_step_count, S4.abs_step_count,
											//Encoder_GetSpeedRPM(&E1), Encoder_GetSpeedRPM(&E2),
											//Encoder_GetSpeedRPM(&E3), Encoder_GetSpeedRPM(&E4)
											b1_target_rpm, b2_target_rpm,
											b3_target_rpm, b4_target_rpm);
					 if (HAL_UART_Transmit_DMA(&huart5, feedback_buf, tel_len) == HAL_OK){
						 uart_tx_ready = 0;
						 lastTransmissionTime = HAL_GetTick();
					 }
				 }
			}
#endif
			control_loop = 0;
		}
#if TELEMETRY_OWNS_UART5
		tel_service(&huart5);
#endif

    /* USER CODE END WHILE */

    /* USER CODE BEGIN 3 */

  }

  Encoder_free(&E1);
  Encoder_free(&E2);
  Encoder_free(&E3);
  Encoder_free(&E4);
  /* USER CODE END 3 */
}

void SystemClock_Config(void)
{
  RCC_OscInitTypeDef RCC_OscInitStruct = {0};
  RCC_ClkInitTypeDef RCC_ClkInitStruct = {0};

  /** Configure the main internal regulator output voltage
  */
  HAL_PWREx_ControlVoltageScaling(PWR_REGULATOR_VOLTAGE_SCALE1_BOOST);

  /** Initializes the RCC Oscillators according to the specified parameters
  * in the RCC_OscInitTypeDef structure.
  */
  RCC_OscInitStruct.OscillatorType = RCC_OSCILLATORTYPE_HSE;
  RCC_OscInitStruct.HSEState = RCC_HSE_ON;
  RCC_OscInitStruct.PLL.PLLState = RCC_PLL_ON;
  RCC_OscInitStruct.PLL.PLLSource = RCC_PLLSOURCE_HSE;
  RCC_OscInitStruct.PLL.PLLM = RCC_PLLM_DIV6;
  RCC_OscInitStruct.PLL.PLLN = 85;
  RCC_OscInitStruct.PLL.PLLP = RCC_PLLP_DIV2;
  RCC_OscInitStruct.PLL.PLLQ = RCC_PLLQ_DIV2;
  RCC_OscInitStruct.PLL.PLLR = RCC_PLLR_DIV2;
  if (HAL_RCC_OscConfig(&RCC_OscInitStruct) != HAL_OK)
  {
    Error_Handler();
  }

  /** Initializes the CPU, AHB and APB buses clocks
  */
  RCC_ClkInitStruct.ClockType = RCC_CLOCKTYPE_HCLK|RCC_CLOCKTYPE_SYSCLK
                              |RCC_CLOCKTYPE_PCLK1|RCC_CLOCKTYPE_PCLK2;
  RCC_ClkInitStruct.SYSCLKSource = RCC_SYSCLKSOURCE_PLLCLK;
  RCC_ClkInitStruct.AHBCLKDivider = RCC_SYSCLK_DIV1;
  RCC_ClkInitStruct.APB1CLKDivider = RCC_HCLK_DIV1;
  RCC_ClkInitStruct.APB2CLKDivider = RCC_HCLK_DIV1;

  if (HAL_RCC_ClockConfig(&RCC_ClkInitStruct, FLASH_LATENCY_4) != HAL_OK)
  {
    Error_Handler();
  }
}

static void MX_TIM1_Init(void)
{

  TIM_Encoder_InitTypeDef sConfig = {0};
  TIM_MasterConfigTypeDef sMasterConfig = {0};

  htim1.Instance = TIM1;
  htim1.Init.Prescaler = 0;
  htim1.Init.CounterMode = TIM_COUNTERMODE_UP;
  htim1.Init.Period = 65535;
  htim1.Init.ClockDivision = TIM_CLOCKDIVISION_DIV1;
  htim1.Init.RepetitionCounter = 0;
  htim1.Init.AutoReloadPreload = TIM_AUTORELOAD_PRELOAD_DISABLE;
  sConfig.EncoderMode = TIM_ENCODERMODE_TI12;
  sConfig.IC1Polarity = TIM_ICPOLARITY_RISING;
  sConfig.IC1Selection = TIM_ICSELECTION_DIRECTTI;
  sConfig.IC1Prescaler = TIM_ICPSC_DIV1;
  sConfig.IC1Filter = 10;
  sConfig.IC2Polarity = TIM_ICPOLARITY_RISING;
  sConfig.IC2Selection = TIM_ICSELECTION_DIRECTTI;
  sConfig.IC2Prescaler = TIM_ICPSC_DIV1;
  sConfig.IC2Filter = 10;
  if (HAL_TIM_Encoder_Init(&htim1, &sConfig) != HAL_OK)
  {
    Error_Handler();
  }
  sMasterConfig.MasterOutputTrigger = TIM_TRGO_RESET;
  sMasterConfig.MasterOutputTrigger2 = TIM_TRGO2_RESET;
  sMasterConfig.MasterSlaveMode = TIM_MASTERSLAVEMODE_DISABLE;
  if (HAL_TIMEx_MasterConfigSynchronization(&htim1, &sMasterConfig) != HAL_OK)
  {
    Error_Handler();
  }

}

static void MX_TIM2_Init(void)
{

  TIM_Encoder_InitTypeDef sConfig = {0};
  TIM_MasterConfigTypeDef sMasterConfig = {0};

  htim2.Instance = TIM2;
  htim2.Init.Prescaler = 0;
  htim2.Init.CounterMode = TIM_COUNTERMODE_UP;
  htim2.Init.Period = 65535;
  htim2.Init.ClockDivision = TIM_CLOCKDIVISION_DIV1;
  htim2.Init.AutoReloadPreload = TIM_AUTORELOAD_PRELOAD_DISABLE;
  sConfig.EncoderMode = TIM_ENCODERMODE_TI12;
  sConfig.IC1Polarity = TIM_ICPOLARITY_RISING;
  sConfig.IC1Selection = TIM_ICSELECTION_DIRECTTI;
  sConfig.IC1Prescaler = TIM_ICPSC_DIV1;
  sConfig.IC1Filter = 10;
  sConfig.IC2Polarity = TIM_ICPOLARITY_RISING;
  sConfig.IC2Selection = TIM_ICSELECTION_DIRECTTI;
  sConfig.IC2Prescaler = TIM_ICPSC_DIV1;
  sConfig.IC2Filter = 10;
  if (HAL_TIM_Encoder_Init(&htim2, &sConfig) != HAL_OK)
  {
    Error_Handler();
  }
  sMasterConfig.MasterOutputTrigger = TIM_TRGO_RESET;
  sMasterConfig.MasterSlaveMode = TIM_MASTERSLAVEMODE_DISABLE;
  if (HAL_TIMEx_MasterConfigSynchronization(&htim2, &sMasterConfig) != HAL_OK)
  {
    Error_Handler();
  }

}

static void MX_TIM3_Init(void)
{

  TIM_MasterConfigTypeDef sMasterConfig = {0};
  TIM_OC_InitTypeDef sConfigOC = {0};

  htim3.Instance = TIM3;
  htim3.Init.Prescaler = 0;
  htim3.Init.CounterMode = TIM_COUNTERMODE_UP;
  htim3.Init.Period = 8499;
  htim3.Init.ClockDivision = TIM_CLOCKDIVISION_DIV1;
  htim3.Init.AutoReloadPreload = TIM_AUTORELOAD_PRELOAD_DISABLE;
  if (HAL_TIM_PWM_Init(&htim3) != HAL_OK)
  {
    Error_Handler();
  }
  sMasterConfig.MasterOutputTrigger = TIM_TRGO_RESET;
  sMasterConfig.MasterSlaveMode = TIM_MASTERSLAVEMODE_DISABLE;
  if (HAL_TIMEx_MasterConfigSynchronization(&htim3, &sMasterConfig) != HAL_OK)
  {
    Error_Handler();
  }
  sConfigOC.OCMode = TIM_OCMODE_PWM1;
  sConfigOC.Pulse = 0;
  sConfigOC.OCPolarity = TIM_OCPOLARITY_HIGH;
  sConfigOC.OCFastMode = TIM_OCFAST_DISABLE;
  if (HAL_TIM_PWM_ConfigChannel(&htim3, &sConfigOC, TIM_CHANNEL_1) != HAL_OK)
  {
    Error_Handler();
  }
  if (HAL_TIM_PWM_ConfigChannel(&htim3, &sConfigOC, TIM_CHANNEL_2) != HAL_OK)
  {
    Error_Handler();
  }
  if (HAL_TIM_PWM_ConfigChannel(&htim3, &sConfigOC, TIM_CHANNEL_3) != HAL_OK)
  {
    Error_Handler();
  }
  if (HAL_TIM_PWM_ConfigChannel(&htim3, &sConfigOC, TIM_CHANNEL_4) != HAL_OK)
  {
    Error_Handler();
  }
  HAL_TIM_MspPostInit(&htim3);

}

static void MX_TIM4_Init(void)
{

  TIM_Encoder_InitTypeDef sConfig = {0};
  TIM_MasterConfigTypeDef sMasterConfig = {0};

  htim4.Instance = TIM4;
  htim4.Init.Prescaler = 0;
  htim4.Init.CounterMode = TIM_COUNTERMODE_UP;
  htim4.Init.Period = 65535;
  htim4.Init.ClockDivision = TIM_CLOCKDIVISION_DIV1;
  htim4.Init.AutoReloadPreload = TIM_AUTORELOAD_PRELOAD_DISABLE;
  sConfig.EncoderMode = TIM_ENCODERMODE_TI12;
  sConfig.IC1Polarity = TIM_ICPOLARITY_RISING;
  sConfig.IC1Selection = TIM_ICSELECTION_DIRECTTI;
  sConfig.IC1Prescaler = TIM_ICPSC_DIV1;
  sConfig.IC1Filter = 10;
  sConfig.IC2Polarity = TIM_ICPOLARITY_RISING;
  sConfig.IC2Selection = TIM_ICSELECTION_DIRECTTI;
  sConfig.IC2Prescaler = TIM_ICPSC_DIV1;
  sConfig.IC2Filter = 10;
  if (HAL_TIM_Encoder_Init(&htim4, &sConfig) != HAL_OK)
  {
    Error_Handler();
  }
  sMasterConfig.MasterOutputTrigger = TIM_TRGO_RESET;
  sMasterConfig.MasterSlaveMode = TIM_MASTERSLAVEMODE_DISABLE;
  if (HAL_TIMEx_MasterConfigSynchronization(&htim4, &sMasterConfig) != HAL_OK)
  {
    Error_Handler();
  }

}

static void MX_TIM6_Init(void)
{

  TIM_MasterConfigTypeDef sMasterConfig = {0};

  htim6.Instance = TIM6;
  htim6.Init.Prescaler = 169;
  htim6.Init.CounterMode = TIM_COUNTERMODE_UP;
  htim6.Init.Period = 9999;
  htim6.Init.AutoReloadPreload = TIM_AUTORELOAD_PRELOAD_DISABLE;
  if (HAL_TIM_Base_Init(&htim6) != HAL_OK)
  {
    Error_Handler();
  }
  sMasterConfig.MasterOutputTrigger = TIM_TRGO_RESET;
  sMasterConfig.MasterSlaveMode = TIM_MASTERSLAVEMODE_DISABLE;
  if (HAL_TIMEx_MasterConfigSynchronization(&htim6, &sMasterConfig) != HAL_OK)
  {
    Error_Handler();
  }

}

static void MX_TIM8_Init(void)
{

  TIM_Encoder_InitTypeDef sConfig = {0};
  TIM_MasterConfigTypeDef sMasterConfig = {0};

  htim8.Instance = TIM8;
  htim8.Init.Prescaler = 0;
  htim8.Init.CounterMode = TIM_COUNTERMODE_UP;
  htim8.Init.Period = 65535;
  htim8.Init.ClockDivision = TIM_CLOCKDIVISION_DIV1;
  htim8.Init.RepetitionCounter = 0;
  htim8.Init.AutoReloadPreload = TIM_AUTORELOAD_PRELOAD_DISABLE;
  sConfig.EncoderMode = TIM_ENCODERMODE_TI12;
  sConfig.IC1Polarity = TIM_ICPOLARITY_RISING;
  sConfig.IC1Selection = TIM_ICSELECTION_DIRECTTI;
  sConfig.IC1Prescaler = TIM_ICPSC_DIV1;
  sConfig.IC1Filter = 10;
  sConfig.IC2Polarity = TIM_ICPOLARITY_RISING;
  sConfig.IC2Selection = TIM_ICSELECTION_DIRECTTI;
  sConfig.IC2Prescaler = TIM_ICPSC_DIV1;
  sConfig.IC2Filter = 10;
  if (HAL_TIM_Encoder_Init(&htim8, &sConfig) != HAL_OK)
  {
    Error_Handler();
  }
  sMasterConfig.MasterOutputTrigger = TIM_TRGO_RESET;
  sMasterConfig.MasterOutputTrigger2 = TIM_TRGO2_RESET;
  sMasterConfig.MasterSlaveMode = TIM_MASTERSLAVEMODE_DISABLE;
  if (HAL_TIMEx_MasterConfigSynchronization(&htim8, &sMasterConfig) != HAL_OK)
  {
    Error_Handler();
  }

}

static void MX_TIM15_Init(void)
{

  TIM_MasterConfigTypeDef sMasterConfig = {0};
  TIM_OC_InitTypeDef sConfigOC = {0};
  TIM_BreakDeadTimeConfigTypeDef sBreakDeadTimeConfig = {0};

  htim15.Instance = TIM15;
  htim15.Init.Prescaler = 125;
  htim15.Init.CounterMode = TIM_COUNTERMODE_UP;
  htim15.Init.Period = 3;
  htim15.Init.ClockDivision = TIM_CLOCKDIVISION_DIV1;
  htim15.Init.RepetitionCounter = 0;
  htim15.Init.AutoReloadPreload = TIM_AUTORELOAD_PRELOAD_ENABLE;
  if (HAL_TIM_PWM_Init(&htim15) != HAL_OK)
  {
    Error_Handler();
  }
  if (HAL_TIM_OnePulse_Init(&htim15, TIM_OPMODE_SINGLE) != HAL_OK)
  {
    Error_Handler();
  }
  sMasterConfig.MasterOutputTrigger = TIM_TRGO_RESET;
  sMasterConfig.MasterSlaveMode = TIM_MASTERSLAVEMODE_DISABLE;
  if (HAL_TIMEx_MasterConfigSynchronization(&htim15, &sMasterConfig) != HAL_OK)
  {
    Error_Handler();
  }
  sConfigOC.OCMode = TIM_OCMODE_PWM1;
  sConfigOC.Pulse = 0;
  sConfigOC.OCPolarity = TIM_OCPOLARITY_LOW;
  sConfigOC.OCNPolarity = TIM_OCNPOLARITY_HIGH;
  sConfigOC.OCFastMode = TIM_OCFAST_DISABLE;
  sConfigOC.OCIdleState = TIM_OCIDLESTATE_RESET;
  sConfigOC.OCNIdleState = TIM_OCNIDLESTATE_RESET;
  if (HAL_TIM_PWM_ConfigChannel(&htim15, &sConfigOC, TIM_CHANNEL_1) != HAL_OK)
  {
    Error_Handler();
  }
  sBreakDeadTimeConfig.OffStateRunMode = TIM_OSSR_DISABLE;
  sBreakDeadTimeConfig.OffStateIDLEMode = TIM_OSSI_DISABLE;
  sBreakDeadTimeConfig.LockLevel = TIM_LOCKLEVEL_OFF;
  sBreakDeadTimeConfig.DeadTime = 0;
  sBreakDeadTimeConfig.BreakState = TIM_BREAK_DISABLE;
  sBreakDeadTimeConfig.BreakPolarity = TIM_BREAKPOLARITY_HIGH;
  sBreakDeadTimeConfig.BreakFilter = 0;
  sBreakDeadTimeConfig.AutomaticOutput = TIM_AUTOMATICOUTPUT_DISABLE;
  if (HAL_TIMEx_ConfigBreakDeadTime(&htim15, &sBreakDeadTimeConfig) != HAL_OK)
  {
    Error_Handler();
  }
  HAL_TIM_MspPostInit(&htim15);

}

static void MX_TIM16_Init(void)
{

  TIM_OC_InitTypeDef sConfigOC = {0};
  TIM_BreakDeadTimeConfigTypeDef sBreakDeadTimeConfig = {0};

  htim16.Instance = TIM16;
  htim16.Init.Prescaler = 125;
  htim16.Init.CounterMode = TIM_COUNTERMODE_UP;
  htim16.Init.Period = 3;
  htim16.Init.ClockDivision = TIM_CLOCKDIVISION_DIV1;
  htim16.Init.RepetitionCounter = 0;
  htim16.Init.AutoReloadPreload = TIM_AUTORELOAD_PRELOAD_ENABLE;
  if (HAL_TIM_Base_Init(&htim16) != HAL_OK)
  {
    Error_Handler();
  }
  if (HAL_TIM_PWM_Init(&htim16) != HAL_OK)
  {
    Error_Handler();
  }
  if (HAL_TIM_OnePulse_Init(&htim16, TIM_OPMODE_SINGLE) != HAL_OK)
  {
    Error_Handler();
  }
  sConfigOC.OCMode = TIM_OCMODE_PWM1;
  sConfigOC.Pulse = 0;
  sConfigOC.OCPolarity = TIM_OCPOLARITY_LOW;
  sConfigOC.OCNPolarity = TIM_OCNPOLARITY_HIGH;
  sConfigOC.OCFastMode = TIM_OCFAST_DISABLE;
  sConfigOC.OCIdleState = TIM_OCIDLESTATE_RESET;
  sConfigOC.OCNIdleState = TIM_OCNIDLESTATE_RESET;
  if (HAL_TIM_PWM_ConfigChannel(&htim16, &sConfigOC, TIM_CHANNEL_1) != HAL_OK)
  {
    Error_Handler();
  }
  sBreakDeadTimeConfig.OffStateRunMode = TIM_OSSR_DISABLE;
  sBreakDeadTimeConfig.OffStateIDLEMode = TIM_OSSI_DISABLE;
  sBreakDeadTimeConfig.LockLevel = TIM_LOCKLEVEL_OFF;
  sBreakDeadTimeConfig.DeadTime = 0;
  sBreakDeadTimeConfig.BreakState = TIM_BREAK_DISABLE;
  sBreakDeadTimeConfig.BreakPolarity = TIM_BREAKPOLARITY_HIGH;
  sBreakDeadTimeConfig.BreakFilter = 0;
  sBreakDeadTimeConfig.AutomaticOutput = TIM_AUTOMATICOUTPUT_DISABLE;
  if (HAL_TIMEx_ConfigBreakDeadTime(&htim16, &sBreakDeadTimeConfig) != HAL_OK)
  {
    Error_Handler();
  }
  HAL_TIM_MspPostInit(&htim16);

}

static void MX_TIM17_Init(void)
{

  TIM_OC_InitTypeDef sConfigOC = {0};
  TIM_BreakDeadTimeConfigTypeDef sBreakDeadTimeConfig = {0};

  htim17.Instance = TIM17;
  htim17.Init.Prescaler = 125;
  htim17.Init.CounterMode = TIM_COUNTERMODE_UP;
  htim17.Init.Period = 3;
  htim17.Init.ClockDivision = TIM_CLOCKDIVISION_DIV1;
  htim17.Init.RepetitionCounter = 0;
  htim17.Init.AutoReloadPreload = TIM_AUTORELOAD_PRELOAD_ENABLE;
  if (HAL_TIM_Base_Init(&htim17) != HAL_OK)
  {
    Error_Handler();
  }
  if (HAL_TIM_PWM_Init(&htim17) != HAL_OK)
  {
    Error_Handler();
  }
  if (HAL_TIM_OnePulse_Init(&htim17, TIM_OPMODE_SINGLE) != HAL_OK)
  {
    Error_Handler();
  }
  sConfigOC.OCMode = TIM_OCMODE_PWM1;
  sConfigOC.Pulse = 0;
  sConfigOC.OCPolarity = TIM_OCPOLARITY_LOW;
  sConfigOC.OCNPolarity = TIM_OCNPOLARITY_HIGH;
  sConfigOC.OCFastMode = TIM_OCFAST_DISABLE;
  sConfigOC.OCIdleState = TIM_OCIDLESTATE_RESET;
  sConfigOC.OCNIdleState = TIM_OCNIDLESTATE_RESET;
  if (HAL_TIM_PWM_ConfigChannel(&htim17, &sConfigOC, TIM_CHANNEL_1) != HAL_OK)
  {
    Error_Handler();
  }
  sBreakDeadTimeConfig.OffStateRunMode = TIM_OSSR_DISABLE;
  sBreakDeadTimeConfig.OffStateIDLEMode = TIM_OSSI_DISABLE;
  sBreakDeadTimeConfig.LockLevel = TIM_LOCKLEVEL_OFF;
  sBreakDeadTimeConfig.DeadTime = 0;
  sBreakDeadTimeConfig.BreakState = TIM_BREAK_DISABLE;
  sBreakDeadTimeConfig.BreakPolarity = TIM_BREAKPOLARITY_HIGH;
  sBreakDeadTimeConfig.BreakFilter = 0;
  sBreakDeadTimeConfig.AutomaticOutput = TIM_AUTOMATICOUTPUT_DISABLE;
  if (HAL_TIMEx_ConfigBreakDeadTime(&htim17, &sBreakDeadTimeConfig) != HAL_OK)
  {
    Error_Handler();
  }
  HAL_TIM_MspPostInit(&htim17);

}

static void MX_TIM20_Init(void)
{

  TIM_MasterConfigTypeDef sMasterConfig = {0};
  TIM_OC_InitTypeDef sConfigOC = {0};
  TIM_BreakDeadTimeConfigTypeDef sBreakDeadTimeConfig = {0};

  htim20.Instance = TIM20;
  htim20.Init.Prescaler = 125;
  htim20.Init.CounterMode = TIM_COUNTERMODE_UP;
  htim20.Init.Period = 3;
  htim20.Init.ClockDivision = TIM_CLOCKDIVISION_DIV1;
  htim20.Init.RepetitionCounter = 0;
  htim20.Init.AutoReloadPreload = TIM_AUTORELOAD_PRELOAD_ENABLE;
  if (HAL_TIM_PWM_Init(&htim20) != HAL_OK)
  {
    Error_Handler();
  }
  if (HAL_TIM_OnePulse_Init(&htim20, TIM_OPMODE_SINGLE) != HAL_OK)
  {
    Error_Handler();
  }
  sMasterConfig.MasterOutputTrigger = TIM_TRGO_RESET;
  sMasterConfig.MasterOutputTrigger2 = TIM_TRGO2_RESET;
  sMasterConfig.MasterSlaveMode = TIM_MASTERSLAVEMODE_DISABLE;
  if (HAL_TIMEx_MasterConfigSynchronization(&htim20, &sMasterConfig) != HAL_OK)
  {
    Error_Handler();
  }
  sConfigOC.OCMode = TIM_OCMODE_PWM1;
  sConfigOC.Pulse = 0;
  sConfigOC.OCPolarity = TIM_OCPOLARITY_LOW;
  sConfigOC.OCNPolarity = TIM_OCNPOLARITY_HIGH;
  sConfigOC.OCFastMode = TIM_OCFAST_DISABLE;
  sConfigOC.OCIdleState = TIM_OCIDLESTATE_RESET;
  sConfigOC.OCNIdleState = TIM_OCNIDLESTATE_RESET;
  if (HAL_TIM_PWM_ConfigChannel(&htim20, &sConfigOC, TIM_CHANNEL_1) != HAL_OK)
  {
    Error_Handler();
  }
  sBreakDeadTimeConfig.OffStateRunMode = TIM_OSSR_DISABLE;
  sBreakDeadTimeConfig.OffStateIDLEMode = TIM_OSSI_DISABLE;
  sBreakDeadTimeConfig.LockLevel = TIM_LOCKLEVEL_OFF;
  sBreakDeadTimeConfig.DeadTime = 0;
  sBreakDeadTimeConfig.BreakState = TIM_BREAK_DISABLE;
  sBreakDeadTimeConfig.BreakPolarity = TIM_BREAKPOLARITY_HIGH;
  sBreakDeadTimeConfig.BreakFilter = 0;
  sBreakDeadTimeConfig.BreakAFMode = TIM_BREAK_AFMODE_INPUT;
  sBreakDeadTimeConfig.Break2State = TIM_BREAK2_DISABLE;
  sBreakDeadTimeConfig.Break2Polarity = TIM_BREAK2POLARITY_HIGH;
  sBreakDeadTimeConfig.Break2Filter = 0;
  sBreakDeadTimeConfig.Break2AFMode = TIM_BREAK_AFMODE_INPUT;
  sBreakDeadTimeConfig.AutomaticOutput = TIM_AUTOMATICOUTPUT_DISABLE;
  if (HAL_TIMEx_ConfigBreakDeadTime(&htim20, &sBreakDeadTimeConfig) != HAL_OK)
  {
    Error_Handler();
  }
  HAL_TIM_MspPostInit(&htim20);

}

static void MX_UART5_Init(void)
{

  huart5.Instance = UART5;
  huart5.Init.BaudRate = 921600;
  huart5.Init.WordLength = UART_WORDLENGTH_8B;
  huart5.Init.StopBits = UART_STOPBITS_1;
  huart5.Init.Parity = UART_PARITY_NONE;
  huart5.Init.Mode = UART_MODE_TX_RX;
  huart5.Init.HwFlowCtl = UART_HWCONTROL_NONE;
  huart5.Init.OverSampling = UART_OVERSAMPLING_16;
  huart5.Init.OneBitSampling = UART_ONE_BIT_SAMPLE_DISABLE;
  huart5.Init.ClockPrescaler = UART_PRESCALER_DIV1;
  huart5.AdvancedInit.AdvFeatureInit = UART_ADVFEATURE_NO_INIT;
  if (HAL_UART_Init(&huart5) != HAL_OK)
  {
    Error_Handler();
  }
  if (HAL_UARTEx_SetTxFifoThreshold(&huart5, UART_TXFIFO_THRESHOLD_1_8) != HAL_OK)
  {
    Error_Handler();
  }
  if (HAL_UARTEx_SetRxFifoThreshold(&huart5, UART_RXFIFO_THRESHOLD_1_8) != HAL_OK)
  {
    Error_Handler();
  }
  if (HAL_UARTEx_DisableFifoMode(&huart5) != HAL_OK)
  {
    Error_Handler();
  }

}

static void MX_USART2_UART_Init(void)
{

  huart2.Instance = USART2;
  huart2.Init.BaudRate = 115200;
  huart2.Init.WordLength = UART_WORDLENGTH_8B;
  huart2.Init.StopBits = UART_STOPBITS_1;
  huart2.Init.Parity = UART_PARITY_NONE;
  huart2.Init.Mode = UART_MODE_TX_RX;
  huart2.Init.HwFlowCtl = UART_HWCONTROL_NONE;
  huart2.Init.OverSampling = UART_OVERSAMPLING_16;
  huart2.Init.OneBitSampling = UART_ONE_BIT_SAMPLE_DISABLE;
  huart2.Init.ClockPrescaler = UART_PRESCALER_DIV1;
  huart2.AdvancedInit.AdvFeatureInit = UART_ADVFEATURE_NO_INIT;
  if (HAL_UART_Init(&huart2) != HAL_OK)
  {
    Error_Handler();
  }
  if (HAL_UARTEx_SetTxFifoThreshold(&huart2, UART_TXFIFO_THRESHOLD_1_8) != HAL_OK)
  {
    Error_Handler();
  }
  if (HAL_UARTEx_SetRxFifoThreshold(&huart2, UART_RXFIFO_THRESHOLD_1_8) != HAL_OK)
  {
    Error_Handler();
  }
  if (HAL_UARTEx_DisableFifoMode(&huart2) != HAL_OK)
  {
    Error_Handler();
  }

}

static void MX_DMA_Init(void)
{

  /* DMA controller clock enable */
  __HAL_RCC_DMAMUX1_CLK_ENABLE();
  __HAL_RCC_DMA1_CLK_ENABLE();

  /* DMA interrupt init */
  /* DMA1_Channel1_IRQn interrupt configuration */
  HAL_NVIC_SetPriority(DMA1_Channel1_IRQn, 0, 0);
  HAL_NVIC_EnableIRQ(DMA1_Channel1_IRQn);
  /* DMA1_Channel2_IRQn interrupt configuration */
  HAL_NVIC_SetPriority(DMA1_Channel2_IRQn, 0, 0);
  HAL_NVIC_EnableIRQ(DMA1_Channel2_IRQn);

}

static void MX_GPIO_Init(void)
{
  GPIO_InitTypeDef GPIO_InitStruct = {0};

  /* GPIO Ports Clock Enable */
  __HAL_RCC_GPIOC_CLK_ENABLE();
  __HAL_RCC_GPIOF_CLK_ENABLE();
  __HAL_RCC_GPIOA_CLK_ENABLE();
  __HAL_RCC_GPIOB_CLK_ENABLE();
  __HAL_RCC_GPIOD_CLK_ENABLE();

  /*Configure GPIO pin Output Level */
  HAL_GPIO_WritePin(GPIOC, S1_ENA_Pin|S2_ENA_Pin|B4_DIR_Pin|S4_DIR_Pin
                          |B3_DIR_Pin, GPIO_PIN_RESET);

  /*Configure GPIO pin Output Level */
  HAL_GPIO_WritePin(GPIOA, S4_ENA_Pin|S2_DIR_Pin, GPIO_PIN_RESET);

  /*Configure GPIO pin Output Level */
  HAL_GPIO_WritePin(GPIOB, S3_DIR_Pin|B2_DIR_Pin|B1_DIR_Pin|S3_ENA_Pin
                          |S1_DIR_Pin, GPIO_PIN_RESET);

  /*Configure GPIO pins : S1_LIM_Pin S4_LIM_Pin S3_LIM_Pin */
  GPIO_InitStruct.Pin = S1_LIM_Pin|S4_LIM_Pin|S3_LIM_Pin;
  GPIO_InitStruct.Mode = GPIO_MODE_IT_FALLING;
  GPIO_InitStruct.Pull = GPIO_PULLDOWN;
  HAL_GPIO_Init(GPIOC, &GPIO_InitStruct);

  /*Configure GPIO pins : S1_ENA_Pin S2_ENA_Pin B4_DIR_Pin S4_DIR_Pin
                           B3_DIR_Pin */
  GPIO_InitStruct.Pin = S1_ENA_Pin|S2_ENA_Pin|B4_DIR_Pin|S4_DIR_Pin
                          |B3_DIR_Pin;
  GPIO_InitStruct.Mode = GPIO_MODE_OUTPUT_PP;
  GPIO_InitStruct.Pull = GPIO_NOPULL;
  GPIO_InitStruct.Speed = GPIO_SPEED_FREQ_LOW;
  HAL_GPIO_Init(GPIOC, &GPIO_InitStruct);

  /*Configure GPIO pins : S4_ENA_Pin S2_DIR_Pin */
  GPIO_InitStruct.Pin = S4_ENA_Pin|S2_DIR_Pin;
  GPIO_InitStruct.Mode = GPIO_MODE_OUTPUT_PP;
  GPIO_InitStruct.Pull = GPIO_NOPULL;
  GPIO_InitStruct.Speed = GPIO_SPEED_FREQ_LOW;
  HAL_GPIO_Init(GPIOA, &GPIO_InitStruct);

  /*Configure GPIO pins : S3_DIR_Pin B2_DIR_Pin B1_DIR_Pin S3_ENA_Pin
                           S1_DIR_Pin */
  GPIO_InitStruct.Pin = S3_DIR_Pin|B2_DIR_Pin|B1_DIR_Pin|S3_ENA_Pin
                          |S1_DIR_Pin;
  GPIO_InitStruct.Mode = GPIO_MODE_OUTPUT_PP;
  GPIO_InitStruct.Pull = GPIO_NOPULL;
  GPIO_InitStruct.Speed = GPIO_SPEED_FREQ_LOW;
  HAL_GPIO_Init(GPIOB, &GPIO_InitStruct);

  /*Configure GPIO pins : ESTOP_Pin S2_LIM_Pin */
  GPIO_InitStruct.Pin = ESTOP_Pin|S2_LIM_Pin;
  GPIO_InitStruct.Mode = GPIO_MODE_IT_FALLING;
  GPIO_InitStruct.Pull = GPIO_PULLDOWN;
  HAL_GPIO_Init(GPIOB, &GPIO_InitStruct);

  /* EXTI interrupt init*/
  HAL_NVIC_SetPriority(EXTI9_5_IRQn, 0, 0);
  HAL_NVIC_EnableIRQ(EXTI9_5_IRQn);

  HAL_NVIC_SetPriority(EXTI15_10_IRQn, 0, 0);
  HAL_NVIC_EnableIRQ(EXTI15_10_IRQn);

}

/* USER CODE BEGIN 4 */
void HAL_TIM_PeriodElapsedCallback(TIM_HandleTypeDef *htim){
	// check timer for interrupt
	if(htim->Instance == TIM6){
		control_loop = 1;
		tel_mark_isr();
		return;
	}
	Stepper_Handle_t *s = NULL;

	/* Identify stepper */
	if (htim->Instance == S1.step_timer->Instance) s = &S1;
	else if (htim->Instance == S2.step_timer->Instance) s = &S2;
	else if (htim->Instance == S3.step_timer->Instance) s = &S3;
	else if (htim->Instance == S4.step_timer->Instance) s = &S4;
	else return;

	/* If not moving, nothing to do */
	if (!s->isMoving)
	    return;

	/* A burst has completed */
	uint32_t completed = s->last_burst_size;

	s->totalPulses += completed;
	s->abs_step_count += s->dir * completed;

	/* Preemption check */
	if (s->pending_preemption)
	{
	    s->target_steps = 0;
	    Stepper_Stop(s);
	    s->pending_preemption = 0;
	    return;
	}

	/* More steps remaining? */
	/* More steps remaining? */
	if (s->target_steps > completed)
	{
	    s->target_steps -= completed;

	    uint32_t next_chunk = (s->target_steps > BURST_SIZE)
	                        ? BURST_SIZE : s->target_steps;
	    s->last_burst_size = next_chunk;

	    // Timer is already stopped at this point (fired its last pulse)
	    // but be explicit
	    __HAL_TIM_DISABLE(s->step_timer);
	    __HAL_TIM_DISABLE_IT(s->step_timer, TIM_IT_UPDATE);

	    s->step_timer->Instance->RCR = next_chunk - 1;
	    __HAL_TIM_SET_COUNTER(s->step_timer, 0);

	    s->step_timer->Instance->EGR = TIM_EGR_UG;
	    __HAL_TIM_CLEAR_FLAG(s->step_timer, TIM_FLAG_UPDATE);  // clear AFTER EGR

	    // untested for estop:
	    // If the EXTI E-stop fired while we were doing the math above, abort!
		if (!s->isMoving) return;

	    __HAL_TIM_ENABLE_IT(s->step_timer, TIM_IT_UPDATE);
	    __HAL_TIM_ENABLE(s->step_timer);
	}
	else
	{
	    s->target_steps = 0;
	    if (s->correctOffset == 2) {
	    	s->homing_status = 1;
	    	s->abs_step_count = 0;
		    s->correctOffset = 0;
	    }
	    //s->totalPulses = 0; //optional
	    Stepper_Stop(s);
	}
}

void HAL_UARTEx_RxEventCallback(UART_HandleTypeDef *huart, uint16_t Size)
{
    if (huart->Instance == UART5)
    {
    	static uint16_t old_pos = 0;
		static uint16_t shadow_idx = 0;
		uint16_t len = 0;

		// copy chunk from DMA buffer into accumulator
		if (Size > old_pos) {			// linear buffer
			len = Size - old_pos;
			memcpy(&shadow_rx_buf[shadow_idx], &rx_buf[old_pos], len);
		}
		else if (Size < old_pos) {		// wrap-around in buffer
			len = rx_buf_size - old_pos;
			memcpy(&shadow_rx_buf[shadow_idx], &rx_buf[old_pos], len);
			memcpy(&shadow_rx_buf[shadow_idx + len], rx_buf, Size);
			len += Size;
		}

		shadow_idx += len;
		shadow_rx_buf[shadow_idx] = '\0'; // seal string
		old_pos = Size;

		// last semi-colon in string
		char *last_semi = strrchr((char*)shadow_rx_buf, ';');
		if (last_semi != NULL) {
			uint16_t split_index = (last_semi - (char*)shadow_rx_buf) + 1;
			uint16_t leftover_len = shadow_idx - split_index;
#if TELEMETRY_OWNS_UART5
			// main loop has not taken the previous block yet: append, don't overwrite
			uint16_t keep = uart_data_ready ? (uint16_t)strlen(main_cmd_buf) : 0;
			if (keep + split_index >= sizeof(main_cmd_buf)) keep = 0;	// overflow: newest wins
			memcpy(&main_cmd_buf[keep], shadow_rx_buf, split_index);
			main_cmd_buf[keep + split_index] = '\0';
#else
			memcpy(main_cmd_buf, shadow_rx_buf, split_index);			// copy complete command into main loop's buffer
			main_cmd_buf[split_index] = '\0';
#endif
			uart_data_ready = 1; // flag main loop

			// save the incomplete fragment ("B3 5" instead of "B3 50") for the next interrupt
			char temp_leftover[64];
			if (leftover_len > 0) {
				memcpy(temp_leftover, &shadow_rx_buf[split_index], leftover_len);
				memcpy(shadow_rx_buf, temp_leftover, leftover_len);
			}
			shadow_idx = leftover_len;
			shadow_rx_buf[shadow_idx] = '\0';
		}
		else if (shadow_idx >= sizeof(shadow_rx_buf) - 10)
			shadow_idx = 0;										// full buffer but no semicolons
    }
}

void HAL_UART_RxCpltCallback(UART_HandleTypeDef *huart)
{
    if (huart->Instance == USART2)
        {

    	switch (bpill_rx_state) {
			case 0:		// look for header
				if (bpill_rx_byte == 0xAA) {
					bpill_rx_buf[0] = bpill_rx_byte;
					bpill_rx_state = 1;
				}
				break;

			case 1:		// get which mode bot is in
				bpill_rx_buf[1] = bpill_rx_byte;
				bpill_rx_state = 2;
				break;

			case 2:		// verify checksum
				bpill_rx_buf[2] = bpill_rx_byte;
				bpill_rx_state = 0;
				// get actual checksum value
				uint8_t expected_checksum = bpill_rx_buf[0] ^ bpill_rx_buf[1];
				if (bpill_rx_buf[2] == expected_checksum) {

//					// in case homing is incomplete (edge case)
//					if (current_true_mode == MODE_HOMING && !(S1.homing_status && S2.homing_status && S3.homing_status && S4.homing_status)){
//						current_true_mode = MODE_HOMING;
//						break;
//					}

					prev_rec_mode = rec_mode;
					rec_mode = bpill_rx_buf[1];					// apply mode if checksum is correct
					last_bpill_hearbeat = HAL_GetTick();		// valid transmission received

					// edge case if bpill tells me to home
					if (rec_mode == MODE_HOMING && prev_rec_mode != MODE_HOMING){
						Stepper_Stop(&S1); Stepper_Stop(&S2);
						Stepper_Stop(&S3); Stepper_Stop(&S4);
						S1.totalPulses = 0;
						S2.totalPulses = 0;
						S3.totalPulses = 0;
						S4.totalPulses = 0;
						S1.homing_status = 0;
						S2.homing_status = 0;
						S3.homing_status = 0;
						S4.homing_status = 0;
						S1.correctOffset = 0;
						S2.correctOffset = 0;
						S3.correctOffset = 0;
						S4.correctOffset = 0;
					}
				}
				//mode = rec_mode;
				break;
		}
			// re-arm interrupt for next byte
			HAL_UART_Receive_IT(huart, &bpill_rx_byte, 1);
        }
}

void HAL_UART_TxCpltCallback(UART_HandleTypeDef *huart)
{
    if (huart->Instance == UART5)
    {
        uart_tx_ready = 1;
        tel_tx_done();
    }
}

void HAL_UART_ErrorCallback(UART_HandleTypeDef *huart){
	if (huart->Instance == UART5){

		error_entered++;					// for debugging
		last_error = huart->ErrorCode;		// check huart5.Instance->ISR in live expressions, might give more info

		// clear flags at error
		__HAL_UART_CLEAR_OREFLAG(huart);
		__HAL_UART_CLEAR_NEFLAG(huart);
		__HAL_UART_CLEAR_FEFLAG(huart);

		// restart UART DMA
		HAL_UART_AbortReceive(huart);
		HAL_UARTEx_ReceiveToIdle_DMA(&huart5, rx_buf, rx_buf_size);
	}

	else if (huart->Instance == USART2){
		// clear flags at error for the bpill link
		uarterror++;
		uarterror3_error = huart->ErrorCode;
		__HAL_UART_CLEAR_OREFLAG(huart);
		__HAL_UART_CLEAR_NEFLAG(huart);
		__HAL_UART_CLEAR_FEFLAG(huart);

		// restart the 1-byte interrupt listener
		HAL_UART_AbortReceive(huart);
		HAL_UART_Receive_IT(&huart2, &bpill_rx_byte, 1);
	}
}

void HAL_GPIO_EXTI_Callback(uint16_t GPIO_Pin){

	if (GPIO_Pin == ESTOP_Pin){
		// noise filter: kyuki EMI = BT
		if (HAL_GPIO_ReadPin(ESTOP_GPIO_Port, ESTOP_Pin) == GPIO_PIN_RESET) {
			estop_active = 1;
			b1_target_rpm = b2_target_rpm = b3_target_rpm = b4_target_rpm = 0;
			PID_Reset(&pid_b1); PID_Reset(&pid_b2); PID_Reset(&pid_b3); PID_Reset(&pid_b4);

			// following is removed because pressing estop mid-stepper rotation caused timer issues causing offset:

//			Stepper_Stop(&S1); Stepper_Stop(&S2); Stepper_Stop(&S3); Stepper_Stop(&S4);
//			initWQueue(&S1.q); initWQueue(&S2.q); initWQueue(&S3.q); initWQueue(&S4.q);
		}
	}

	current_debounce_time = HAL_GetTick();

	if (GPIO_Pin == S1_LIM_Pin){ 						// stepper 1
		if (S1.homing_status || S1.correctOffset == 2) return; //if already homed, do nothing
		if (current_debounce_time - last_debounce_time[0] > DEBOUNCE_TIME_PERIOD){
			last_debounce_time[0] = current_debounce_time;
			Stepper_Stop(&S1);
			S1.correctOffset = 1;
			tel_homing_switch(0);
		}
	}
	if (GPIO_Pin == S2_LIM_Pin){						// stepper 2
		if (S2.homing_status || S2.correctOffset == 2) return; //if already homed, do nothing
		if (current_debounce_time - last_debounce_time[1] > DEBOUNCE_TIME_PERIOD){
			last_debounce_time[1] = current_debounce_time;
			Stepper_Stop(&S2);
			S2.correctOffset = 1;
			tel_homing_switch(1);

		}
	}
	if (GPIO_Pin == S3_LIM_Pin){						// stepper 3
		if (S3.homing_status || S3.correctOffset == 2) return;//if already homed, do nothing
		if (current_debounce_time - last_debounce_time[2] > DEBOUNCE_TIME_PERIOD){
			last_debounce_time[2] = current_debounce_time;
			Stepper_Stop(&S3);
			S3.correctOffset = 1;
			tel_homing_switch(2);
		}
	}
	if (GPIO_Pin == S4_LIM_Pin){						// stepper 4
		if (S4.homing_status || S4.correctOffset == 2) return; //if already homed, do nothing
		if (current_debounce_time - last_debounce_time[3] > DEBOUNCE_TIME_PERIOD){
			last_debounce_time[3] = current_debounce_time;
			Stepper_Stop(&S4);
			S4.correctOffset = 1;
			tel_homing_switch(3);
		}
	}
}

/* USER CODE END 4 */

void Error_Handler(void)
{
  __disable_irq();
  while (1)
  {
  }
}
